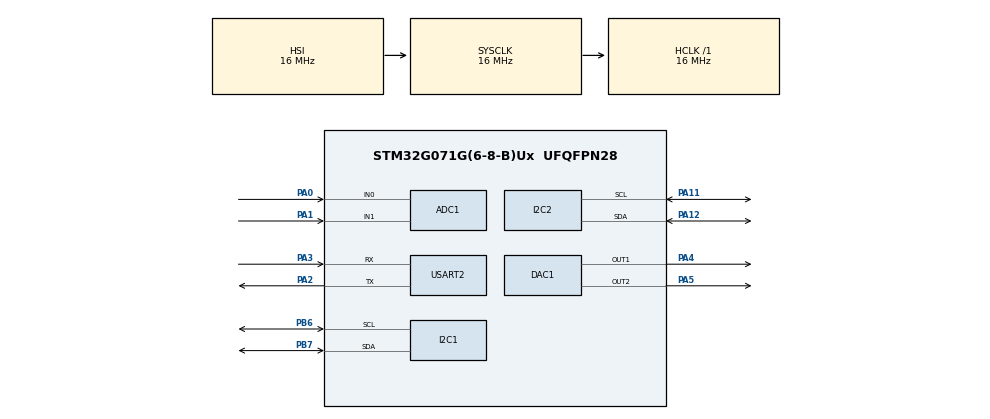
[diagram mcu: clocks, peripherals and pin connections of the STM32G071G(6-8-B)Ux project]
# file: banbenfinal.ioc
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ADC1.Channel-0\#ChannelRegularConversion=ADC_CHANNEL_0
ADC1.Channel-1\#ChannelRegularConversion=ADC_CHANNEL_1
ADC1.ContinuousConvMode=ENABLE
ADC1.NbrOfConversion=2
ADC1.NbrOfConversionFlag=1
ADC1.Rank-0\#ChannelRegularConversion=1
ADC1.Rank-1\#ChannelRegularConversion=2
ADC1.SamplingTime-0\#ChannelRegularConversion=ADC_SAMPLINGTIME_COMMON_1
ADC1.SamplingTime-1\#ChannelRegularConversion=ADC_SAMPLINGTIME_COMMON_2
ADC1.SamplingTimeCommon1=ADC_SAMPLETIME_160CYCLES_5
ADC1.SamplingTimeCommon2=ADC_SAMPLETIME_160CYCLES_5
ADC1.SelectedChannel=ADC_CHANNEL_0|ADC_CHANNEL_1
ADC1.master=1
DAC1.DAC_Channel-DAC_OUT1=DAC_CHANNEL_1
DAC1.DAC_Channel-DAC_OUT2=DAC_CHANNEL_2
I2C1.Timing=0x00503D58
I2C2.Timing=0x00503D58
Mcu.Family=STM32G0
Mcu.Name=STM32G071G(6-8-B)Ux
Mcu.Package=UFQFPN28
NVIC.I2C1_IRQn=true\:0\:0\:false\:false\:true\:true\:true\:true
NVIC.I2C2_IRQn=true\:0\:0\:false\:false\:true\:true\:true\:true
PA0.Mode=IN0
PA0.Signal=ADC1_IN0
PA1.Mode=IN1
PA1.Signal=ADC1_IN1
PA11\ [PA9].Mode=I2C
PA11\ [PA9].Signal=I2C2_SCL
PA12\ [PA10].Mode=I2C
PA12\ [PA10].Signal=I2C2_SDA
PA13.Mode=Serial_Wire
PA13.Signal=SYS_SWDIO
PA14-BOOT0.Mode=Serial_Wire
PA14-BOOT0.Signal=SYS_SWCLK
PA2.Mode=Asynchronous
PA2.Signal=USART2_TX
PA3.Mode=Asynchronous
PA3.Signal=USART2_RX
PA4.Signal=COMP_DAC11_group
PA5.Signal=COMP_DAC12_group
PB6.Mode=I2C
PB6.Signal=I2C1_SCL
PB7.Mode=I2C
PB7.Signal=I2C1_SDA
ProjectManager.HeapSize=0x200
ProjectManager.StackSize=0x400
ProjectManager.TargetToolchain=CMake
RCC.AHBFreq_Value=16000000
RCC.CortexFreq_Value=16000000
RCC.EXTERNAL_CLOCK_VALUE=48000
RCC.HCLKFreq_Value=16000000
RCC.HSE_VALUE=8000000
RCC.HSI_VALUE=16000000
RCC.LSE_VALUE=32768
RCC.SYSCLKFreq_VALUE=16000000
RCC.VCOOutputFreq_Value=128000000
SH.COMP_DAC11_group.0=DAC1_OUT1,DAC_OUT1
SH.COMP_DAC12_group.0=DAC1_OUT2,DAC_OUT2
USART2.VirtualMode-Asynchronous=VM_ASYNC
board=custom

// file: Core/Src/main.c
/* USER CODE BEGIN Header */
/**
  ******************************************************************************
  * @file           : main.c
  * @brief          : Main program body
  ******************************************************************************
  * @attention
  *
  * Copyright (c) 2026 STMicroelectronics.
  * All rights reserved.
  *
  * This software is licensed under terms that can be found in the LICENSE file
  * in the root directory of this software component.
  * If no LICENSE file comes with this software, it is provided AS-IS.
  *
  ******************************************************************************
  */
/* USER CODE END Header */
#include "main.h"
#include "adc.h"
#include "dac.h"
#include "i2c.h"
#include "usart.h"
#include "gpio.h"
#include "smart_button.h"

void SystemClock_Config(void);

int main(void)
{

  /* MCU Configuration--------------------------------------------------------*/

  /* Reset of all peripherals, Initializes the Flash interface and the Systick. */
  HAL_Init();

  /* Configure the system clock */
  SystemClock_Config();

  /* Initialize all configured peripherals */
  MX_GPIO_Init();
  MX_ADC1_Init();
  MX_DAC1_Init();
  MX_I2C1_Init();
  MX_I2C2_Init();
  MX_USART2_UART_Init();
  /* USER CODE BEGIN 2 */
  SmartBtn_System_Init();
  /* USER CODE END 2 */

  /* Infinite loop */
  while (1)
  {
    SmartBtn_System_Tick();
  }
}

void SystemClock_Config(void)
{
  RCC_OscInitTypeDef RCC_OscInitStruct = {0};
  RCC_ClkInitTypeDef RCC_ClkInitStruct = {0};

  /** Configure the main internal regulator output voltage
  */
  HAL_PWREx_ControlVoltageScaling(PWR_REGULATOR_VOLTAGE_SCALE1);

  /** Initializes the RCC Oscillators according to the specified parameters
  * in the RCC_OscInitTypeDef structure.
  */
  RCC_OscInitStruct.OscillatorType = RCC_OSCILLATORTYPE_HSI;
  RCC_OscInitStruct.HSIState = RCC_HSI_ON;
  RCC_OscInitStruct.HSIDiv = RCC_HSI_DIV1;
  RCC_OscInitStruct.HSICalibrationValue = RCC_HSICALIBRATION_DEFAULT;
  RCC_OscInitStruct.PLL.PLLState = RCC_PLL_NONE;
  if (HAL_RCC_OscConfig(&RCC_OscInitStruct) != HAL_OK)
  {
    Error_Handler();
  }

  /** Initializes the CPU, AHB and APB buses clocks
  */
  RCC_ClkInitStruct.ClockType = RCC_CLOCKTYPE_HCLK|RCC_CLOCKTYPE_SYSCLK
                              |RCC_CLOCKTYPE_PCLK1;
  RCC_ClkInitStruct.SYSCLKSource = RCC_SYSCLKSOURCE_HSI;
  RCC_ClkInitStruct.AHBCLKDivider = RCC_SYSCLK_DIV1;
  RCC_ClkInitStruct.APB1CLKDivider = RCC_HCLK_DIV1;

  if (HAL_RCC_ClockConfig(&RCC_ClkInitStruct, FLASH_LATENCY_0) != HAL_OK)
  {
    Error_Handler();
  }
}

void Error_Handler(void)
{
  __disable_irq();
  while (1)
  {
  }
}
